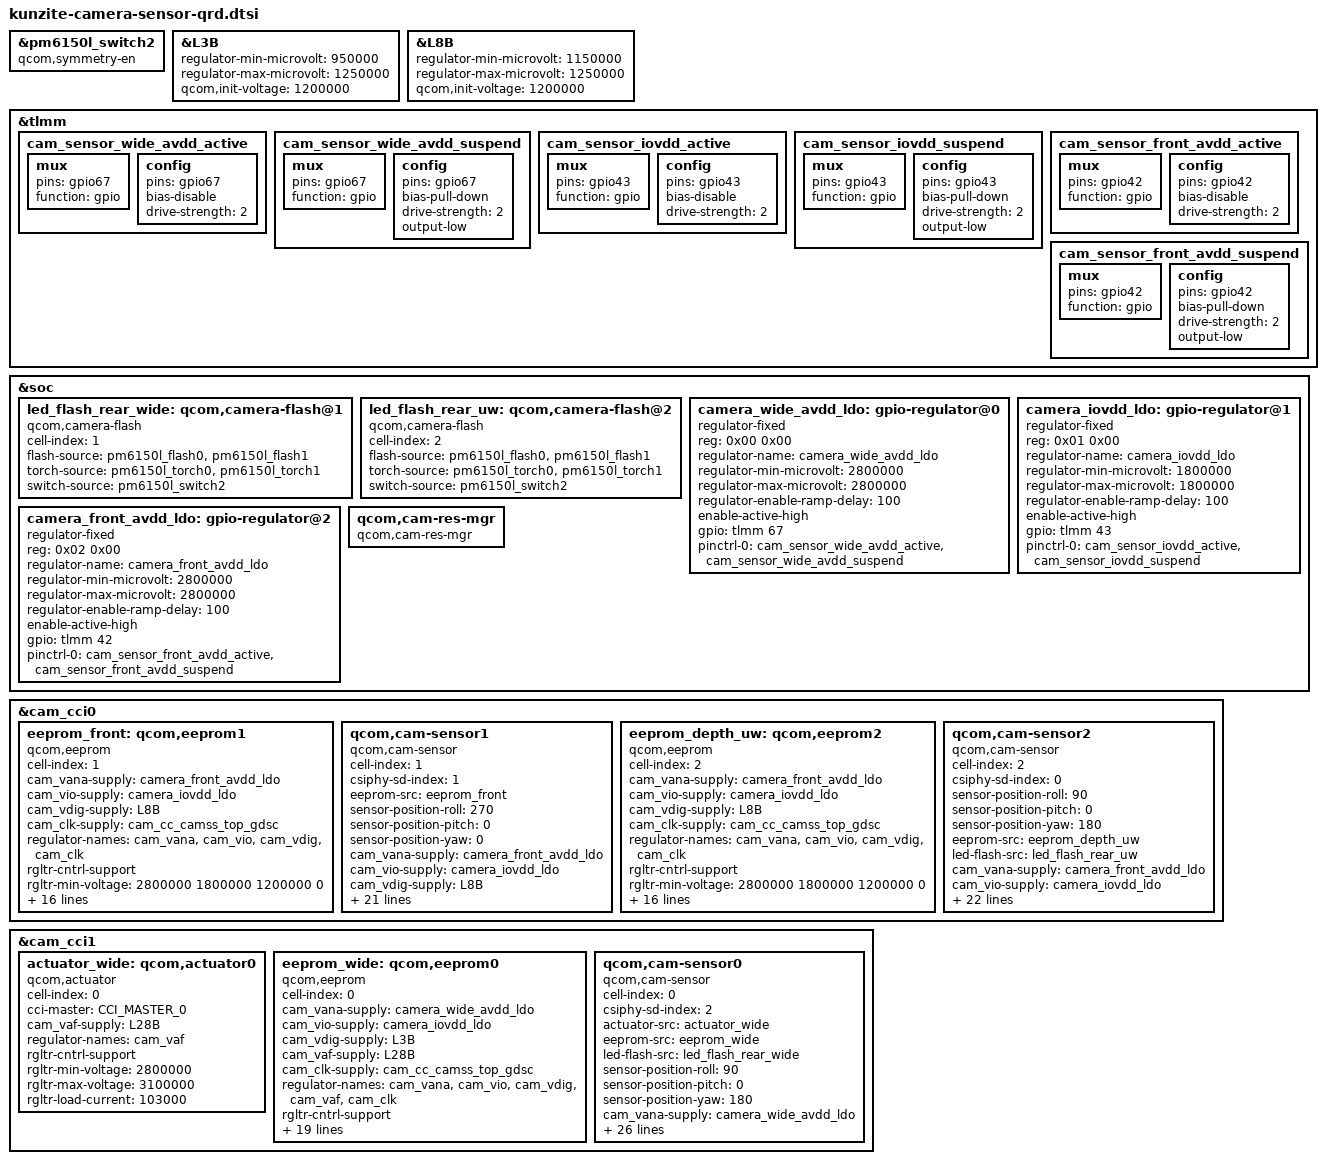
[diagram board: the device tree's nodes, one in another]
#include <dt-bindings/clock/qcom,camcc-parrot.h>
#include <dt-bindings/msm-camera.h>

&pm6150l_switch2 {
	qcom,symmetry-en;
};

&L3B {
	regulator-min-microvolt = <950000>;
	regulator-max-microvolt = <1250000>;
	qcom,init-voltage = <1200000>;
};

&L8B {
	regulator-min-microvolt = <1150000>;
	regulator-max-microvolt = <1250000>;
	qcom,init-voltage = <1200000>;
};

&tlmm {
	cam_sensor_wide_avdd_active: cam_sensor_wide_avdd_active {
		mux {
			pins = "gpio67";
			function = "gpio";
		};

		config {
			pins = "gpio67";
			bias-disable; /* No PULL */
			drive-strength = <2>; /* 2 MA */
		};
	};

	cam_sensor_wide_avdd_suspend: cam_sensor_wide_avdd_suspend {
		mux {
			pins = "gpio67";
			function = "gpio";
		};

		config {
			pins = "gpio67";
			bias-pull-down; /* PULL DOWN */
			drive-strength = <2>; /* 2 MA */
			output-low;
		};
	};
	
	cam_sensor_iovdd_active: cam_sensor_iovdd_active {
		mux {
			pins = "gpio43";
			function = "gpio";
		};

		config {
			pins = "gpio43";
			bias-disable; /* No PULL */
			drive-strength = <2>; /* 2 MA */
		};
	};

	cam_sensor_iovdd_suspend: cam_sensor_iovdd_suspend {
		mux {
			pins = "gpio43";
			function = "gpio";
		};

		config {
			pins = "gpio43";
			bias-pull-down; /* PULL DOWN */
			drive-strength = <2>; /* 2 MA */
			output-low;
		};
	};
	
	cam_sensor_front_avdd_active: cam_sensor_front_avdd_active {
		mux {
			pins = "gpio42";
			function = "gpio";
		};

		config {
			pins = "gpio42";
			bias-disable; /* No PULL */
			drive-strength = <2>; /* 2 MA */
		};
	};

	cam_sensor_front_avdd_suspend: cam_sensor_front_avdd_suspend {
		mux {
			pins = "gpio42";
			function = "gpio";
		};

		config {
			pins = "gpio42";
			bias-pull-down; /* PULL DOWN */
			drive-strength = <2>; /* 2 MA */
			output-low;
		};
	};
};

&soc {
	led_flash_rear_wide: qcom,camera-flash@1 {
		cell-index = <1>;
		compatible = "qcom,camera-flash";
		flash-source = <&pm6150l_flash0 &pm6150l_flash1>;
		torch-source = <&pm6150l_torch0 &pm6150l_torch1>;
		switch-source = <&pm6150l_switch2>;
		status = "ok";
	};

	led_flash_rear_uw: qcom,camera-flash@2 {
		cell-index = <2>;
		compatible = "qcom,camera-flash";
		flash-source = <&pm6150l_flash0 &pm6150l_flash1>;
		torch-source = <&pm6150l_torch0 &pm6150l_torch1>;
		switch-source = <&pm6150l_switch2>;
		status = "ok";
	};

	camera_wide_avdd_ldo: gpio-regulator@0 {
		compatible = "regulator-fixed";
		reg = <0x00 0x00>;
		regulator-name = "camera_wide_avdd_ldo";
		regulator-min-microvolt = <2800000>;
		regulator-max-microvolt = <2800000>;
		regulator-enable-ramp-delay = <100>;
		enable-active-high;
		gpio = <&tlmm 67 0>;
		pinctrl-names = "wide_avdd_active", "wide_avdd_suspend";
		pinctrl-0 = <&cam_sensor_wide_avdd_active
					 &cam_sensor_wide_avdd_suspend>;
	};

	camera_iovdd_ldo: gpio-regulator@1 {
		compatible = "regulator-fixed";
		reg = <0x01 0x00>;
		regulator-name = "camera_iovdd_ldo";
		regulator-min-microvolt = <1800000>;
		regulator-max-microvolt = <1800000>;
		regulator-enable-ramp-delay = <100>;
		enable-active-high;
		gpio = <&tlmm 43 0>;
		pinctrl-names = "iovdd_active", "iovdd_suspend";
		pinctrl-0 = <&cam_sensor_iovdd_active
					 &cam_sensor_iovdd_suspend>;
	};

	camera_front_avdd_ldo: gpio-regulator@2 {
		compatible = "regulator-fixed";
		reg = <0x02 0x00>;
		regulator-name = "camera_front_avdd_ldo";
		regulator-min-microvolt = <2800000>;
		regulator-max-microvolt = <2800000>;
		regulator-enable-ramp-delay = <100>;
		enable-active-high;
		gpio = <&tlmm 42 0>;
		pinctrl-names = "front_avdd_active", "front_avdd_suspend";
		pinctrl-0 = <&cam_sensor_front_avdd_active
					 &cam_sensor_front_avdd_suspend>;
	};

	qcom,cam-res-mgr {
		compatible = "qcom,cam-res-mgr";
		status = "ok";
	};
};

&cam_cci0 {
	eeprom_front: qcom,eeprom1 {
		cell-index = <1>;
		compatible = "qcom,eeprom";
		cam_vana-supply = <&camera_front_avdd_ldo>;
		cam_vio-supply = <&camera_iovdd_ldo>;
		cam_vdig-supply = <&L8B>;
		cam_clk-supply = <&cam_cc_camss_top_gdsc>;
		regulator-names = "cam_vana", "cam_vio", "cam_vdig",
			"cam_clk";
		rgltr-cntrl-support;
		rgltr-min-voltage = <2800000 1800000 1200000 0>;
		rgltr-max-voltage = <2800000 1800000 1200000 0>;
		rgltr-load-current = <50000 50000 50000 0>;
		gpio-no-mux = <0>;
		pinctrl-names = "cam_default", "cam_suspend";
		pinctrl-0 = <&cam_sensor_mclk0_active
			&cam_sensor_active_rst0>;
		pinctrl-1 = <&cam_sensor_mclk0_suspend
			&cam_sensor_suspend_rst0>;
		gpios = <&tlmm 39 0>, <&tlmm 44 0>;
		gpio-reset = <1>;
		gpio-req-tbl-num = <0 1>;
		gpio-req-tbl-flags = <1 0>;
		gpio-req-tbl-label = "CAMIF_MCLK0", "CAM_RESET0";
		cci-master = <CCI_MASTER_0>;
		clocks = <&camcc CAM_CC_MCLK0_CLK>;
		clock-names = "cam_clk";
		clock-cntl-level = "nominal";
		clock-rates = <19200000>;
		status = "ok";
	};

// front sensor
	qcom,cam-sensor1 {
		cell-index = <1>;
		compatible = "qcom,cam-sensor";
		csiphy-sd-index = <1>;
		eeprom-src = <&eeprom_front>;
		sensor-position-roll = <270>;
		sensor-position-pitch = <0>;
		sensor-position-yaw = <0>;
		cam_vana-supply = <&camera_front_avdd_ldo>;
		cam_vio-supply = <&camera_iovdd_ldo>;
		cam_vdig-supply = <&L8B>;
		cam_clk-supply = <&cam_cc_camss_top_gdsc>;
		regulator-names = "cam_vana", "cam_vio", "cam_vdig",
			"cam_clk";
		rgltr-cntrl-support;
		rgltr-min-voltage = <2800000 1800000 1200000 0>;
		rgltr-max-voltage = <2800000 1800000 1200000 0>;
		rgltr-load-current = <50000 50000 50000 0>;
		gpio-no-mux = <0>;
		pinctrl-names = "cam_default", "cam_suspend";
		pinctrl-0 = <&cam_sensor_mclk0_active
			&cam_sensor_active_rst0>;
		pinctrl-1 = <&cam_sensor_mclk0_suspend
			&cam_sensor_suspend_rst0>;
		gpios = <&tlmm 39 0>, <&tlmm 44 0>;
		gpio-reset = <1>;
		gpio-req-tbl-num = <0 1>;
		gpio-req-tbl-flags = <1 0>;
		gpio-req-tbl-label = "CAMIF_MCLK0", "CAM_RESET0";
		cci-master = <CCI_MASTER_0>;
		clocks = <&camcc CAM_CC_MCLK0_CLK>;
		clock-names = "cam_clk";
		clock-cntl-level = "nominal";
		clock-rates = <19200000>;
		status = "ok";
	};

	eeprom_depth_uw: qcom,eeprom2 {
		cell-index = <2>;
		compatible = "qcom,eeprom";
		cam_vana-supply = <&camera_front_avdd_ldo>;
		cam_vio-supply = <&camera_iovdd_ldo>;
		cam_vdig-supply = <&L8B>;
		cam_clk-supply = <&cam_cc_camss_top_gdsc>;
		regulator-names = "cam_vana", "cam_vio", "cam_vdig", "cam_clk";
		rgltr-cntrl-support;
		rgltr-min-voltage = <2800000 1800000 1200000 0>;
		rgltr-max-voltage = <2800000 1800000 1200000 0>;
		rgltr-load-current = <50000 50000 50000 0>;
		gpio-no-mux = <0>;
		pinctrl-names = "cam_default", "cam_suspend";
		pinctrl-0 = <&cam_sensor_mclk1_active &cam_sensor_active_rst1>;
		pinctrl-1 = <&cam_sensor_mclk1_suspend &cam_sensor_suspend_rst1>;
		gpios = <&tlmm 40 0>, <&tlmm 45 0>;
		gpio-reset = <1>;
		gpio-req-tbl-num = <0 1>;
		gpio-req-tbl-flags = <1 0>;
		gpio-req-tbl-label = "CAMIF_MCLK1", "CAM_RESET1";
		cci-master = <CCI_MASTER_1>;
		clocks = <&camcc CAM_CC_MCLK1_CLK>;
		clock-names = "cam_clk";
		clock-cntl-level = "nominal";
		clock-rates = <19200000>;
		status = "ok";
	};

//depth sensor
	qcom,cam-sensor2 {
		cell-index = <2>;
		compatible = "qcom,cam-sensor";
		csiphy-sd-index = <0>;
		sensor-position-roll = <90>;
		sensor-position-pitch = <0>;
		sensor-position-yaw = <180>;
		eeprom-src = <&eeprom_depth_uw>;
		led-flash-src = <&led_flash_rear_uw>;
		cam_vana-supply = <&camera_front_avdd_ldo>;
		cam_vio-supply = <&camera_iovdd_ldo>;
		cam_vdig-supply = <&L8B>;
		cam_clk-supply = <&cam_cc_camss_top_gdsc>;
		regulator-names = "cam_vana", "cam_vio", "cam_vdig", "cam_clk";
		rgltr-cntrl-support;
		rgltr-min-voltage = <2800000 1800000 1200000 0>;
		rgltr-max-voltage = <2800000 1800000 1200000 0>;
		rgltr-load-current = <50000 50000 50000 0>;
		gpio-no-mux = <0>;
		pinctrl-names = "cam_default", "cam_suspend";
		pinctrl-0 = <&cam_sensor_mclk1_active &cam_sensor_active_rst1>;
		pinctrl-1 = <&cam_sensor_mclk1_suspend &cam_sensor_suspend_rst1>;
		gpios = <&tlmm 40 0>, <&tlmm 45 0>;
		gpio-reset = <1>;
		gpio-req-tbl-num = <0 1>;
		gpio-req-tbl-flags = <1 0>;
		gpio-req-tbl-label = "CAMIF_MCLK1", "CAM_RESET1";
		cci-master = <CCI_MASTER_1>;
		clocks = <&camcc CAM_CC_MCLK1_CLK>;
		clock-names = "cam_clk";
		clock-cntl-level = "nominal";
		clock-rates = <19200000>;
		status = "ok";
	};
};

&cam_cci1 {
	actuator_wide: qcom,actuator0 {
		cell-index = <0>;
		compatible = "qcom,actuator";
		cci-master = <CCI_MASTER_0>;
		cam_vaf-supply = <&L28B>;
		regulator-names = "cam_vaf";
		rgltr-cntrl-support;
		rgltr-min-voltage = <2800000>;
		rgltr-max-voltage = <3100000>;
		rgltr-load-current = <103000>;
	};

	eeprom_wide: qcom,eeprom0 {
		cell-index = <0>;
		compatible = "qcom,eeprom";
		cam_vana-supply = <&camera_wide_avdd_ldo>;
		cam_vio-supply = <&camera_iovdd_ldo>;
		cam_vdig-supply = <&L3B>;
		cam_vaf-supply = <&L28B>;
		cam_clk-supply = <&cam_cc_camss_top_gdsc>;
		regulator-names = "cam_vana", "cam_vio", "cam_vdig", "cam_vaf",
			 "cam_clk";
		rgltr-cntrl-support;
		rgltr-min-voltage = <2800000  1800000 1000000 2800000 0>;
		rgltr-max-voltage = <2800000  1800000 1200000 3100000 0>;
		rgltr-load-current = <50000   50000 50000 50000 0>;
		//use-shared-clk;
		gpio-no-mux = <0>;
		pinctrl-names = "cam_default", "cam_suspend";
		pinctrl-0 = <&cam_sensor_mclk2_active
			&cam_sensor_active_rst2>;
		pinctrl-1 = <&cam_sensor_mclk2_suspend
			&cam_sensor_suspend_rst2>;
		gpios = <&tlmm 41 0>, <&tlmm 46 0>;
		gpio-reset = <1>;
		gpio-req-tbl-num = <0 1>;
		gpio-req-tbl-flags = <1 0>;
		gpio-req-tbl-label = "CAMIF_MCLK2", "CAM_RESET2";
		cci-master = <CCI_MASTER_0>;
		clocks = <&camcc CAM_CC_MCLK2_CLK>;
		clock-names = "cam_clk";
		clock-cntl-level = "nominal";
		clock-rates = <19200000>;
		status = "ok";
	};

	// wide sensor
	qcom,cam-sensor0 {
		cell-index = <0>;
		compatible = "qcom,cam-sensor";
		csiphy-sd-index = <2>;
		actuator-src = <&actuator_wide>;
		eeprom-src = <&eeprom_wide>;
		led-flash-src = <&led_flash_rear_wide>;
		//ois-src = <&ois_wide>;
		sensor-position-roll = <90>;
		sensor-position-pitch = <0>;
		sensor-position-yaw = <180>;
		cam_vana-supply = <&camera_wide_avdd_ldo>;
		cam_vio-supply = <&camera_iovdd_ldo>;
		cam_vdig-supply = <&L3B>;
		cam_vaf-supply = <&L28B>;
		//cam_v_custom1-supply = <&camera_rear_ois_ldo>;
		cam_clk-supply = <&cam_cc_camss_top_gdsc>;
		regulator-names = "cam_vana", "cam_vio", "cam_vdig", "cam_vaf",
			 "cam_clk";
		rgltr-cntrl-support;
		rgltr-min-voltage = <2800000  1800000 1000000 2800000 0>;
		rgltr-max-voltage = <2800000  1800000 1200000 3100000 0>;
		rgltr-load-current = <50000   50000 50000 50000 0>;
		//use-shared-clk;
		gpio-no-mux = <0>;
		pinctrl-names = "cam_default", "cam_suspend";
		pinctrl-0 = <&cam_sensor_mclk2_active
			&cam_sensor_active_rst2>;
		pinctrl-1 = <&cam_sensor_mclk2_suspend
			&cam_sensor_suspend_rst2>;
		gpios = <&tlmm 41 0>, <&tlmm 46 0>;
		gpio-reset = <1>;
		gpio-req-tbl-num = <0 1>;
		gpio-req-tbl-flags = <1 0>;
		gpio-req-tbl-label = "CAMIF_MCLK2", "CAM_RESET2";
		cci-master = <CCI_MASTER_0>;
		clocks = <&camcc CAM_CC_MCLK2_CLK>;
		clock-names = "cam_clk";
		clock-cntl-level = "nominal";
		clock-rates = <19200000>;
		status = "ok";
	};
};
